# f2838x_cm_cm_cputimer_regs register map
Vendor: Texas Instruments
Peripheral module from a debugger description file (folder C2000).
Address unit: 16 bits
Registers are 32-bit, read-write, no defined reset value unless marked. A register's access mark holds for its fields unless they carry their own. Offsets are as the file gives them; lines under a group give offsets from that group; [hi:lo] are bit positions; {n}, {i} and the like mark numbered series; 'fields as' and 'values as' point back to an identical list; <NAME> marks a mode.

## CM_CPUTIMER_REGS — CM CPUTIMER Registers
0x00 TIM — Timer counter register
  [31:0] COUNT — Timer counter
0x04 PRD — Timer period register
  [31:0] PRD — Timer Period
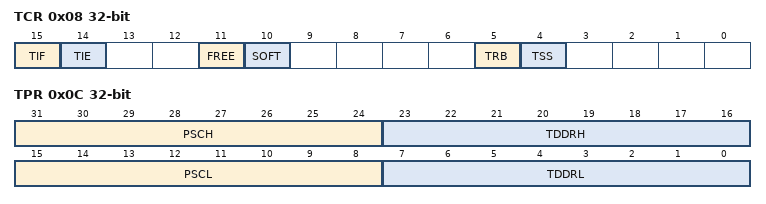
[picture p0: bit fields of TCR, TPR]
0x08 TCR — Timer control register
  [15] TIF — Timer Intrerrupt Flag
  [14] TIE — Timer Interrupt Enable
  [11] FREE — Free run enable
  [10] SOFT — SOFT stop enable
  [5] TRB — Timer Reload Bit
  [4] TSS — Timer Stop Status
0x0C TPR access per field — Timer prescaler register
  [31:24] PSCH ro — Prescaler Counter high
  [23:16] TDDRH rw — Timer Divide Down Register High
  [15:8] PSCL ro — Prescaler Counter low
  [7:0] TDDRL rw — Timer Divide Down Register Low
